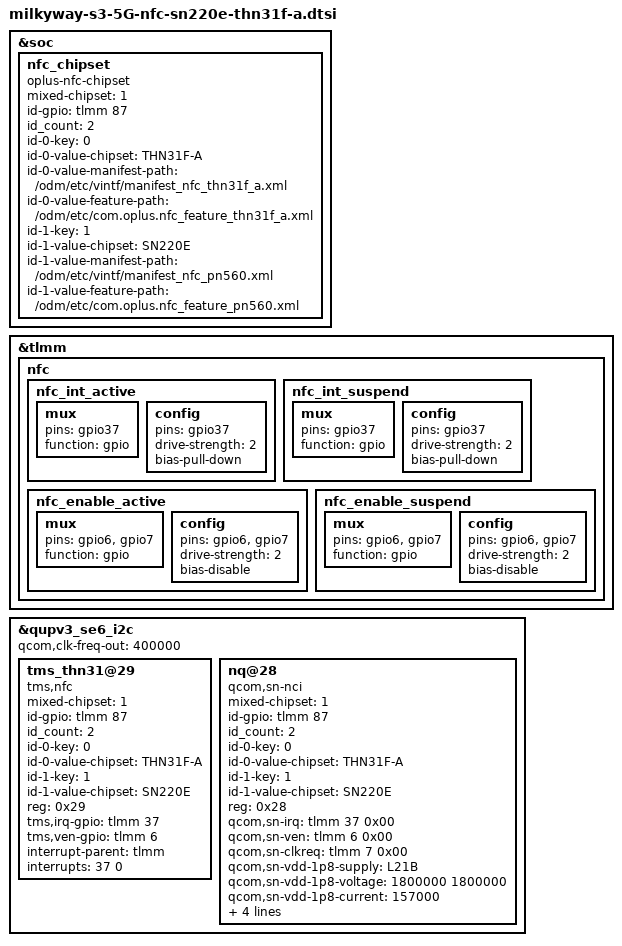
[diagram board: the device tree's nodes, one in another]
&soc {
	//add for nfc_chipset
	nfc_chipset {
		compatible = "oplus-nfc-chipset";
		mixed-chipset = <1>;
		id-gpio = <&tlmm 87 0x00>;
		id_count = <2>;
		id-0-key = <0>;
		id-0-value-chipset = "THN31F-A";
		id-0-value-manifest-path = "/odm/etc/vintf/manifest_nfc_thn31f_a.xml";
		id-0-value-feature-path = "/odm/etc/com.oplus.nfc_feature_thn31f_a.xml";
		id-1-key = <1>;
		id-1-value-chipset = "SN220E";
		id-1-value-manifest-path = "/odm/etc/vintf/manifest_nfc_pn560.xml";
		id-1-value-feature-path = "/odm/etc/com.oplus.nfc_feature_pn560.xml";
	};
};

//&gpio_wakeup {
//	gpio_table = <2 3 6 12 33 38 56 57 88 90 91 92 99 102 108 113 115 116
//						  8 48 51 59 84 85 86 107 117 118 152 153 154 155>;
//};


&tlmm {
	nfc {
		nfc_int_active: nfc_int_active {
			/* active state */
			mux {
				/* NFC Read Interrupt */
				pins = "gpio37";
				function = "gpio";
			};

			config {
				pins = "gpio37";
				drive-strength = <2>; /* 2 MA */
				bias-pull-down;
			};
		};

		nfc_int_suspend: nfc_int_suspend {
			/* sleep state */
			mux {
				/* NFC Read Interrupt */
				pins = "gpio37";
				function = "gpio";
			};

			config {
				pins = "gpio37";
				drive-strength = <2>; /* 2 MA */
				bias-pull-down;
			};
		};

		nfc_enable_active: nfc_enable_active {
			mux {
				/* Enable and Clock request gpios */
				pins = "gpio6", "gpio7";
				function = "gpio";
			};

			config {
				pins = "gpio6", "gpio7";
				drive-strength = <2>; /* 2 MA */
				bias-disable;
			};
		};

		nfc_enable_suspend: nfc_enable_suspend {
			mux {
				pins = "gpio6", "gpio7";
				function = "gpio";
			};

			config {
				pins = "gpio6", "gpio7";
				drive-strength = <2>; /* 2 MA */
				bias-disable;
			};
		};
	}; //nfc
}; //tlmm

&qupv3_se6_i2c {
	status = "ok";
	qcom,clk-freq-out = <400000>;
	#address-cells = <1>;
	#size-cells = <0>;
	tms_thn31@29 {
		compatible = "tms,nfc";
				mixed-chipset = <1>;
		id-gpio = <&tlmm 87 0x00>;
		id_count = <2>;
		id-0-key = <0>;
		id-0-value-chipset = "THN31F-A";
		id-1-key = <1>;
		id-1-value-chipset = "SN220E";
		reg = <0x29>;
		tms,irq-gpio = <&tlmm 37 0x00>;
		tms,ven-gpio = <&tlmm 6 0x00>;
		interrupt-parent = <&tlmm>;
		interrupts = <37 0>;
		interrupt-names = "nfc_irq";
	};
};

&qupv3_se6_i2c {
	status = "ok";
	qcom,clk-freq-out = <400000>;
	#address-cells = <1>;
	#size-cells = <0>;
	nq@28 {
		compatible = "qcom,sn-nci";
		mixed-chipset = <1>;
		id-gpio = <&tlmm 87 0x00>;
		id_count = <2>;
		id-0-key = <0>;
		id-0-value-chipset = "THN31F-A";
		id-1-key = <1>;
		id-1-value-chipset = "SN220E";
		reg = <0x28>;
		qcom,sn-irq = <&tlmm 37 0x00>;
		qcom,sn-ven = <&tlmm 6 0x00>;
		qcom,sn-clkreq = <&tlmm 7 0x00>;
		qcom,sn-vdd-1p8-supply = <&L21B>;
		qcom,sn-vdd-1p8-voltage = <1800000 1800000>;
		qcom,sn-vdd-1p8-current = <157000>;
		interrupt-parent = <&tlmm>;
		interrupts = <37 0>;
		interrupt-names = "nfc_irq";
		pinctrl-names = "nfc_active", "nfc_suspend";
		pinctrl-0 = <&nfc_int_active &nfc_enable_active>;
		pinctrl-1 = <&nfc_int_suspend &nfc_enable_suspend>;
	};
};

